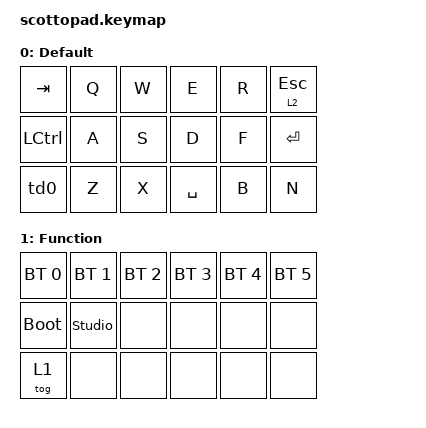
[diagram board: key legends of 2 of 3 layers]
#include <behaviors.dtsi>
#include <dt-bindings/zmk/keys.h>
#include <dt-bindings/zmk/bt.h>

/ {
    behaviors {
        td0: tap_dance_0 {
            compatible = "zmk,behavior-tap-dance";
            #binding-cells = <0>;
            tapping-term-ms = <135>;
            bindings = <&kp LSHIFT>, <&tog 1>;
        };
         lt: layer_tap {
            compatible = "zmk,behavior-hold-tap";
            #binding-cells = <2>;
            flavor = "tap-preferred";
            tapping-term-ms = <200>;
            bindings = <&mo>, <&kp>;
            display-name = "Layer-Tap";
     };
  };

    keymap {
        compatible = "zmk,keymap";

        default_layer {
            display-name = "Default";

            bindings = <
                &kp TAB   &kp Q &kp W &kp E     &kp R &lt 2 ESC
                &kp LCTRL &kp A &kp S &kp D     &kp F &kp ENTER
                &td0      &kp Z &kp X &kp SPACE &kp B &kp N
            >;
        };

        function_layer {
            display-name = "Function";

            bindings =<
                &bt BT_SEL 0 &bt BT_SEL 1   &bt BT_SEL 2 &bt BT_SEL 3 &bt BT_SEL 4 &bt BT_SEL 5
                &bootloader  &studio_unlock &none        &none        &none        &none
                &tog 1       &none          &none        &none        &none        &none
            >;
        };

            numbers_layer {
            display-name = "Numbers";

            bindings =<
                &none &none &none &none &none &none &none
                &none &none &none &none &none &none &none
                &none &none &none &none &none &none &none
            >;
        };
    };
};
